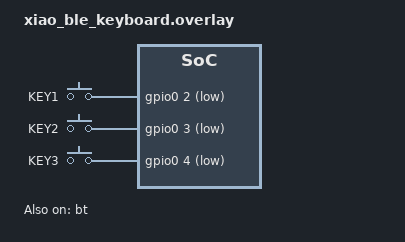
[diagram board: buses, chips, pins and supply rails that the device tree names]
/ {
    keymap {
        compatible = "zmk,keymap";
    };

    gpio-keys {
        compatible = "gpio-keys";
        #address-cells = <1>;
        #size-cells = <0>;

        key_1: key@0 {
            label = "KEY1";
            gpios = <&gpio0 2 GPIO_ACTIVE_LOW>;
            zmk,keycode = <ZMK_KEY_A>;
        };

        key_2: key@1 {
            label = "KEY2";
            gpios = <&gpio0 3 GPIO_ACTIVE_LOW>;
            zmk,keycode = <ZMK_KEY_B>;
        };

        key_3: key@2 {
            label = "KEY3";
            gpios = <&gpio0 4 GPIO_ACTIVE_LOW>;
            zmk,keycode = <ZMK_KEY_C>;
        };
    };
};

&bt {
    status = "okay";
    compatible = "zephyr,bt-cpc-uart";
};

&usb {
    status = "disabled";
};
